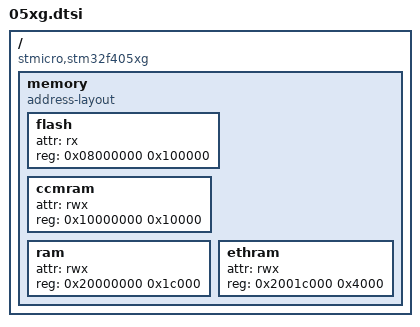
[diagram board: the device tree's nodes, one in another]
/include/ "05.dtsi"

/* STM32F405 with 192KiB SRAM, 1MiB flash */

/ {
    compatible = "stmicro,stm32f405xg", "stmicro,stm32f405", "stmicro,stm32f4";

    memory {
        compatible = "address-layout";
        #address-cells = <1>;
        #size-cells = <1>;

        /* 1MiB flash */
        flash {
            attr = "rx";
            reg = <0x08000000 0x100000>;
        };

        /* 64 KiB CCMRAM */
        ccmram {
            attr = "rwx";
            reg = <0x10000000 0x10000>;
        };

        /* 112KiB SRAM */
        ram {
            attr = "rwx";
            reg = <0x20000000 0x1c000>;
        };

        /* 16KiB ETHRAM */
        ethram {
            attr = "rwx";
            reg = <0x2001c000 0x4000>;
        };
    };
};
